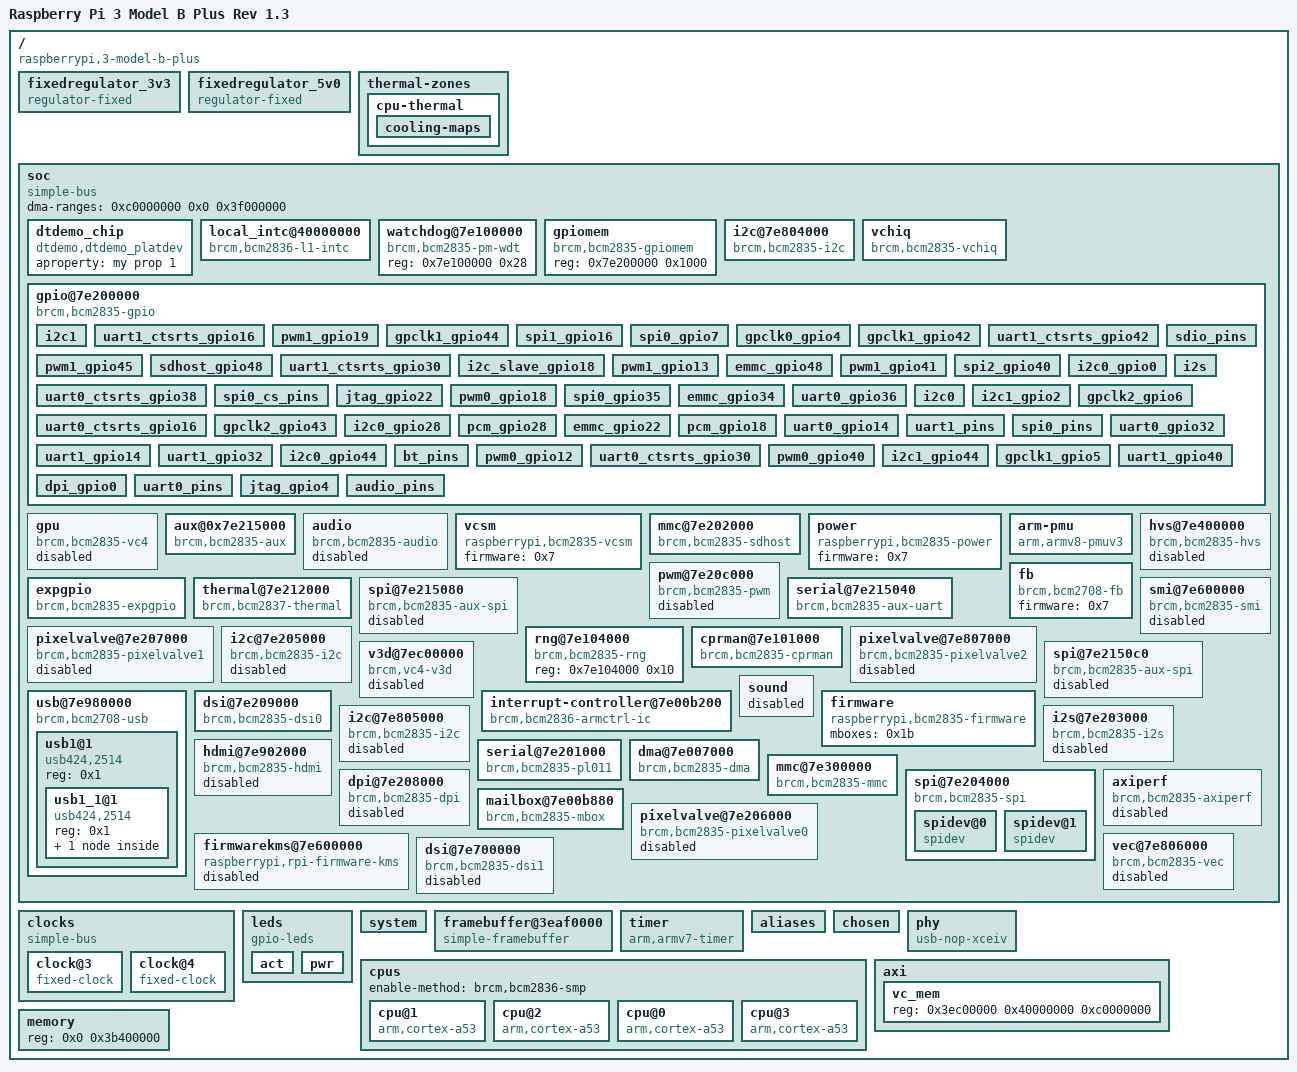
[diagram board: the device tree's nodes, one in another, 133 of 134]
/dts-v1/;

/ {
	#address-cells = <0x1>;
	memreserve = <0x3b400000 0x4c00000>;
	model = "Raspberry Pi 3 Model B Plus Rev 1.3";
	serial-number = "000000000906a583";
	#size-cells = <0x1>;
	interrupt-parent = <0x1>;
	compatible = "raspberrypi,3-model-b-plus", "brcm,bcm2837";

	fixedregulator_3v3 {
		regulator-max-microvolt = <0x325aa0>;
		regulator-always-on;
		regulator-min-microvolt = <0x325aa0>;
		regulator-name = "3v3";
		compatible = "regulator-fixed";
		phandle = <0x74>;
	};

	fixedregulator_5v0 {
		regulator-max-microvolt = <0x4c4b40>;
		regulator-always-on;
		regulator-min-microvolt = <0x4c4b40>;
		regulator-name = "5v0";
		compatible = "regulator-fixed";
		phandle = <0x73>;
	};

	thermal-zones {

		cpu-thermal {
			polling-delay = <0x3e8>;
			polling-delay-passive = <0x0>;
			thermal-sensors = <0x2>;
			phandle = <0x30>;
			coefficients = <0xfffffde6 0x64960>;

			cooling-maps {
			};
		};
	};

	soc {
		dma-ranges = <0xc0000000 0x0 0x3f000000>;
		#address-cells = <0x1>;
		#size-cells = <0x1>;
		compatible = "simple-bus";
		ranges = <0x7e000000 0x3f000000 0x1000000 0x40000000 0x40000000 0x1000>;
		phandle = <0x31>;

		/* our demo pseudo h/w chip
		From DTSpec: https://github.com/devicetree-org/devicetree-specification/releases/download/v0.3-rc2/devicetree-specification-v0.3-rc2.pdf
		 "This list of strings should be used by a client program for device driver selection. The property
value consists of a concatenated list of null terminated strings, from most specific to most general. They
allow a device to express its compatibility with a family of similar devices, potentially allowing a single
device driver to match against several devices. "
		
		*/
		dtdemo_chip {
			compatible = "dtdemo,dtdemo_platdev";
			aproperty = "my prop 1";
		};

		local_intc@40000000 {
			interrupt-parent = <0x3>;
			compatible = "brcm,bcm2836-l1-intc";
			#interrupt-cells = <0x1>;
			reg = <0x40000000 0x100>;
			phandle = <0x3>;
			interrupt-controller;
		};

		watchdog@7e100000 {
			compatible = "brcm,bcm2835-pm-wdt";
			reg = <0x7e100000 0x28>;
			phandle = <0x25>;
		};

		gpiomem {
			compatible = "brcm,bcm2835-gpiomem";
			reg = <0x7e200000 0x1000>;
		};

		i2c@7e804000 {
			pinctrl-names = "default";
			#address-cells = <0x1>;
			pinctrl-0 = <0x14>;
			interrupts = <0x2 0x15>;
			clocks = <0x8 0x14>;
			#size-cells = <0x0>;
			clock-frequency = <0x186a0>;
			compatible = "brcm,bcm2835-i2c";
			status = "okay";
			reg = <0x7e804000 0x1000>;
			phandle = <0x23>;
		};

		vchiq {
			interrupts = <0x0 0x2>;
			compatible = "brcm,bcm2835-vchiq";
			cache-line-size = <0x40>;
			firmware = <0x7>;
			reg = <0x7e00b840 0xf>;
			phandle = <0x1d>;
		};

		gpio@7e200000 {
			gpio-controller;
			interrupts = <0x2 0x11 0x2 0x12>;
			compatible = "brcm,bcm2835-gpio";
			#interrupt-cells = <0x2>;
			reg = <0x7e200000 0xb4>;
			phandle = <0x10>;
			#gpio-cells = <0x2>;
			interrupt-controller;

			i2c1 {
				brcm,function = <0x4>;
				phandle = <0x14>;
				brcm,pins = <0x2 0x3>;
			};

			uart1_ctsrts_gpio16 {
				brcm,function = <0x2>;
				phandle = <0x58>;
				brcm,pins = <0x10 0x11>;
			};

			pwm1_gpio19 {
				brcm,function = <0x2>;
				phandle = <0x4a>;
				brcm,pins = <0x13>;
			};

			gpclk1_gpio44 {
				brcm,function = <0x4>;
				phandle = <0x39>;
				brcm,pins = <0x2c>;
			};

			spi1_gpio16 {
				brcm,function = <0x3>;
				phandle = <0x4f>;
				brcm,pins = <0x10 0x11 0x12 0x13 0x14 0x15>;
			};

			spi0_gpio7 {
				brcm,function = <0x4>;
				phandle = <0x4d>;
				brcm,pins = <0x7 0x8 0x9 0xa 0xb>;
			};

			gpclk0_gpio4 {
				brcm,function = <0x4>;
				phandle = <0x36>;
				brcm,pins = <0x4>;
			};

			gpclk1_gpio42 {
				brcm,function = <0x4>;
				phandle = <0x38>;
				brcm,pins = <0x2a>;
			};

			uart1_ctsrts_gpio42 {
				brcm,function = <0x2>;
				phandle = <0x5c>;
				brcm,pins = <0x2a 0x2b>;
			};

			pwm1_gpio45 {
				brcm,function = <0x4>;
				phandle = <0x4c>;
				brcm,pins = <0x2d>;
			};

			sdhost_gpio48 {
				brcm,function = <0x4>;
				phandle = <0xc>;
				brcm,pins = <0x30 0x31 0x32 0x33 0x34 0x35>;
			};

			uart1_ctsrts_gpio30 {
				brcm,function = <0x2>;
				phandle = <0x5a>;
				brcm,pins = <0x1e 0x1f>;
			};

			i2c_slave_gpio18 {
				brcm,function = <0x7>;
				phandle = <0x41>;
				brcm,pins = <0x12 0x13 0x14 0x15>;
			};

			sdio_pins {
				brcm,pull = <0x0 0x2 0x2 0x2 0x2 0x2>;
				brcm,function = <0x7>;
				phandle = <0x1a>;
				brcm,pins = <0x22 0x23 0x24 0x25 0x26 0x27>;
			};

			pwm1_gpio13 {
				brcm,function = <0x4>;
				phandle = <0x49>;
				brcm,pins = <0xd>;
			};

			emmc_gpio48 {
				brcm,function = <0x7>;
				phandle = <0x35>;
				brcm,pins = <0x30 0x31 0x32 0x33 0x34 0x35>;
			};

			pwm1_gpio41 {
				brcm,function = <0x4>;
				phandle = <0x4b>;
				brcm,pins = <0x29>;
			};

			spi2_gpio40 {
				brcm,function = <0x3>;
				phandle = <0x50>;
				brcm,pins = <0x28 0x29 0x2a 0x2b 0x2c 0x2d>;
			};

			i2c0_gpio0 {
				brcm,function = <0x4>;
				phandle = <0x3c>;
				brcm,pins = <0x0 0x1>;
			};

			uart0_ctsrts_gpio38 {
				brcm,function = <0x6>;
				phandle = <0x56>;
				brcm,pins = <0x26 0x27>;
			};

			spi0_cs_pins {
				brcm,function = <0x1>;
				phandle = <0xf>;
				brcm,pins = <0x8 0x7>;
			};

			jtag_gpio22 {
				brcm,function = <0x3>;
				phandle = <0x43>;
				brcm,pins = <0x16 0x17 0x18 0x19 0x1a 0x1b>;
			};

			i2s {
				brcm,function = <0x4>;
				phandle = <0xd>;
				brcm,pins = <0x12 0x13 0x14 0x15>;
			};

			pwm0_gpio18 {
				brcm,function = <0x2>;
				phandle = <0x47>;
				brcm,pins = <0x12>;
			};

			spi0_gpio35 {
				brcm,function = <0x4>;
				phandle = <0x4e>;
				brcm,pins = <0x23 0x24 0x25 0x26 0x27>;
			};

			emmc_gpio34 {
				brcm,pull = <0x0 0x2 0x2 0x2 0x2 0x2>;
				brcm,function = <0x7>;
				phandle = <0x34>;
				brcm,pins = <0x22 0x23 0x24 0x25 0x26 0x27>;
			};

			uart0_gpio36 {
				brcm,function = <0x6>;
				phandle = <0x55>;
				brcm,pins = <0x24 0x25>;
			};

			i2c0 {
				brcm,function = <0x4>;
				phandle = <0x11>;
				brcm,pins = <0x0 0x1>;
			};

			i2c1_gpio2 {
				brcm,function = <0x4>;
				phandle = <0x3f>;
				brcm,pins = <0x2 0x3>;
			};

			gpclk2_gpio6 {
				brcm,function = <0x4>;
				phandle = <0x3a>;
				brcm,pins = <0x6>;
			};

			uart0_ctsrts_gpio16 {
				brcm,function = <0x7>;
				phandle = <0x52>;
				brcm,pins = <0x10 0x11>;
			};

			gpclk2_gpio43 {
				brcm,function = <0x4>;
				phandle = <0x3b>;
				brcm,pins = <0x2b>;
			};

			i2c0_gpio28 {
				brcm,function = <0x4>;
				phandle = <0x3d>;
				brcm,pins = <0x1c 0x1d>;
			};

			pcm_gpio28 {
				brcm,function = <0x6>;
				phandle = <0x45>;
				brcm,pins = <0x1c 0x1d 0x1e 0x1f>;
			};

			emmc_gpio22 {
				brcm,function = <0x7>;
				phandle = <0x33>;
				brcm,pins = <0x16 0x17 0x18 0x19 0x1a 0x1b>;
			};

			pcm_gpio18 {
				brcm,function = <0x4>;
				phandle = <0x44>;
				brcm,pins = <0x12 0x13 0x14 0x15>;
			};

			uart0_gpio14 {
				brcm,function = <0x4>;
				phandle = <0x51>;
				brcm,pins = <0xe 0xf>;
			};

			uart1_pins {
				brcm,pull;
				brcm,function;
				phandle = <0x13>;
				brcm,pins;
			};

			spi0_pins {
				brcm,function = <0x4>;
				phandle = <0xe>;
				brcm,pins = <0x9 0xa 0xb>;
			};

			uart0_gpio32 {
				brcm,function = <0x7>;
				phandle = <0x54>;
				brcm,pins = <0x20 0x21>;
			};

			uart1_gpio14 {
				brcm,function = <0x2>;
				phandle = <0x57>;
				brcm,pins = <0xe 0xf>;
			};

			uart1_gpio32 {
				brcm,function = <0x2>;
				phandle = <0x59>;
				brcm,pins = <0x20 0x21>;
			};

			i2c0_gpio44 {
				brcm,function = <0x5>;
				phandle = <0x3e>;
				brcm,pins = <0x2c 0x2d>;
			};

			bt_pins {
				brcm,pull = <0x0>;
				brcm,function = <0x4>;
				phandle = <0xa>;
				brcm,pins = <0x2b>;
			};

			pwm0_gpio12 {
				brcm,function = <0x4>;
				phandle = <0x46>;
				brcm,pins = <0xc>;
			};

			uart0_ctsrts_gpio30 {
				brcm,function = <0x7>;
				phandle = <0x53>;
				brcm,pins = <0x1e 0x1f>;
			};

			pwm0_gpio40 {
				brcm,function = <0x4>;
				phandle = <0x48>;
				brcm,pins = <0x28>;
			};

			i2c1_gpio44 {
				brcm,function = <0x6>;
				phandle = <0x40>;
				brcm,pins = <0x2c 0x2d>;
			};

			gpclk1_gpio5 {
				brcm,function = <0x4>;
				phandle = <0x37>;
				brcm,pins = <0x5>;
			};

			uart1_gpio40 {
				brcm,function = <0x2>;
				phandle = <0x5b>;
				brcm,pins = <0x28 0x29>;
			};

			dpi_gpio0 {
				brcm,function = <0x6>;
				phandle = <0x32>;
				brcm,pins = <0x0 0x1 0x2 0x3 0x4 0x5 0x6 0x7 0x8 0x9 0xa 0xb 0xc 0xd 0xe 0xf 0x10 0x11 0x12 0x13 0x14 0x15 0x16 0x17 0x18 0x19 0x1a 0x1b>;
			};

			uart0_pins {
				brcm,pull = <0x2 0x0 0x0 0x2>;
				brcm,function = <0x7>;
				phandle = <0x9>;
				brcm,pins = <0x1e 0x1f 0x20 0x21>;
			};

			jtag_gpio4 {
				brcm,function = <0x2>;
				phandle = <0x42>;
				brcm,pins = <0x4 0x5 0x6 0xc 0xd>;
			};

			audio_pins {
				brcm,function = <0x4>;
				phandle = <0x1c>;
				brcm,pins = <0x28 0x29>;
			};
		};

		gpu {
			compatible = "brcm,bcm2835-vc4";
			status = "disabled";
			phandle = <0x6a>;
		};

		aux@0x7e215000 {
			interrupts = <0x1 0x1d>;
			clocks = <0x8 0x14>;
			#clock-cells = <0x1>;
			compatible = "brcm,bcm2835-aux";
			#interrupt-cells = <0x1>;
			reg = <0x7e215000 0x8>;
			phandle = <0x12>;
			interrupt-controller;
		};

		audio {
			pinctrl-names = "default";
			brcm,pwm-channels = <0x8>;
			pinctrl-0 = <0x1c>;
			compatible = "brcm,bcm2835-audio";
			status = "disabled";
			phandle = <0x24>;
		};

		vcsm {
			compatible = "raspberrypi,bcm2835-vcsm";
			status = "okay";
			firmware = <0x7>;
			phandle = <0x70>;
		};

		mmc@7e202000 {
			pinctrl-names = "default";
			pinctrl-0 = <0xc>;
			bus-width = <0x4>;
			interrupts = <0x2 0x18>;
			clocks = <0x8 0x14>;
			brcm,pio-limit = <0x1>;
			dma-names = "rx-tx";
			compatible = "brcm,bcm2835-sdhost";
			status = "okay";
			reg = <0x7e202000 0x100>;
			phandle = <0x27>;
			dmas = <0xb 0xd>;
			brcm,overclock-50 = <0x0>;
		};

		power {
			#power-domain-cells = <0x1>;
			compatible = "raspberrypi,bcm2835-power";
			firmware = <0x7>;
			phandle = <0x16>;
		};

		arm-pmu {
			interrupts = <0x9>;
			interrupt-parent = <0x3>;
			compatible = "arm,armv8-pmuv3", "arm,cortex-a7-pmu";
		};

		hvs@7e400000 {
			interrupts = <0x2 0x1>;
			compatible = "brcm,bcm2835-hvs";
			status = "disabled";
			reg = <0x7e400000 0x6000>;
			phandle = <0x64>;
		};

		expgpio {
			gpio-controller;
			compatible = "brcm,bcm2835-expgpio";
			status = "okay";
			firmware = <0x7>;
			phandle = <0x17>;
			#gpio-cells = <0x2>;
		};

		pwm@7e20c000 {
			assigned-clocks = <0x8 0x1e>;
			assigned-clock-rates = <0x989680>;
			clocks = <0x8 0x1e>;
			#pwm-cells = <0x2>;
			compatible = "brcm,bcm2835-pwm";
			status = "disabled";
			reg = <0x7e20c000 0x28>;
			phandle = <0x63>;
		};

		fb {
			compatible = "brcm,bcm2708-fb";
			status = "okay";
			firmware = <0x7>;
			phandle = <0x6f>;
		};

		thermal@7e212000 {
			clocks = <0x8 0x1b>;
			#thermal-sensor-cells = <0x0>;
			compatible = "brcm,bcm2837-thermal";
			status = "okay";
			reg = <0x7e212000 0x8>;
			phandle = <0x2>;
		};

		spi@7e215080 {
			#address-cells = <0x1>;
			interrupts = <0x1>;
			clocks = <0x12 0x1>;
			#size-cells = <0x0>;
			interrupt-parent = <0x12>;
			compatible = "brcm,bcm2835-aux-spi";
			status = "disabled";
			reg = <0x7e215080 0x40>;
			phandle = <0x61>;
		};

		serial@7e215040 {
			pinctrl-names = "default";
			pinctrl-0 = <0x13>;
			interrupts = <0x0>;
			clocks = <0x12 0x0>;
			interrupt-parent = <0x12>;
			compatible = "brcm,bcm2835-aux-uart";
			status = "okay";
			reg = <0x7e215040 0x40>;
			phandle = <0x1f>;
		};

		pixelvalve@7e207000 {
			interrupts = <0x2 0xe>;
			compatible = "brcm,bcm2835-pixelvalve1";
			status = "disabled";
			reg = <0x7e207000 0x100>;
			phandle = <0x60>;
		};

		rng@7e104000 {
			compatible = "brcm,bcm2835-rng";
			reg = <0x7e104000 0x10>;
			phandle = <0x26>;
		};

		smi@7e600000 {
			assigned-clocks = <0x8 0x2a>;
			assigned-clock-rates = <0x7735940>;
			interrupts = <0x2 0x10>;
			clocks = <0x8 0x2a>;
			dma-names = "rx-tx";
			compatible = "brcm,bcm2835-smi";
			status = "disabled";
			reg = <0x7e600000 0x100>;
			phandle = <0x6e>;
			dmas = <0xb 0x4>;
		};

		cprman@7e101000 {
			clocks = <0x4 0x5 0x0 0x5 0x1 0x5 0x2 0x6 0x0 0x6 0x1 0x6 0x2>;
			#clock-cells = <0x1>;
			compatible = "brcm,bcm2835-cprman";
			firmware = <0x7>;
			reg = <0x7e101000 0x2000>;
			phandle = <0x8>;
		};

		pixelvalve@7e807000 {
			interrupts = <0x2 0xa>;
			compatible = "brcm,bcm2835-pixelvalve2";
			status = "disabled";
			reg = <0x7e807000 0x100>;
			phandle = <0x66>;
		};

		i2c@7e205000 {
			pinctrl-names = "default";
			#address-cells = <0x1>;
			pinctrl-0 = <0x11>;
			interrupts = <0x2 0x15>;
			clocks = <0x8 0x14>;
			#size-cells = <0x0>;
			clock-frequency = <0x186a0>;
			compatible = "brcm,bcm2835-i2c";
			status = "disabled";
			reg = <0x7e205000 0x1000>;
			phandle = <0x22>;
		};

		v3d@7ec00000 {
			power-domains = <0x16 0xa>;
			interrupts = <0x1 0xa>;
			compatible = "brcm,vc4-v3d";
			status = "disabled";
			reg = <0x7ec00000 0x1000>;
			phandle = <0x69>;
		};

		spi@7e2150c0 {
			#address-cells = <0x1>;
			interrupts = <0x2>;
			clocks = <0x12 0x2>;
			#size-cells = <0x0>;
			interrupt-parent = <0x12>;
			compatible = "brcm,bcm2835-aux-spi";
			status = "disabled";
			reg = <0x7e2150c0 0x40>;
			phandle = <0x62>;
		};

		usb@7e980000 {
			power-domains = <0x16 0x6>;
			#address-cells = <0x1>;
			phy-names = "usb2-phy";
			clock-names = "otg";
			interrupts = <0x2 0x0 0x1 0x9>;
			clocks = <0x18>;
			#size-cells = <0x0>;
			compatible = "brcm,bcm2708-usb";
			phys = <0x19>;
			reg = <0x7e980000 0x10000 0x7e006000 0x1000>;
			phandle = <0x68>;

			usb1@1 {
				#address-cells = <0x1>;
				#size-cells = <0x0>;
				compatible = "usb424,2514";
				reg = <0x1>;

				usb1_1@1 {
					#address-cells = <0x1>;
					#size-cells = <0x0>;
					compatible = "usb424,2514";
					reg = <0x1>;

					usbether@1 {
						local-mac-address = [b8 27 eb 06 a5 83];
						microchip,led-modes = <0x1 0x6>;
						microchip,tx-lpi-timer = <0x258>;
						compatible = "usb424,7800";
						reg = <0x1>;
						phandle = <0x2d>;
						microchip,eee-enabled;
					};
				};
			};
		};

		interrupt-controller@7e00b200 {
			interrupts = <0x8>;
			interrupt-parent = <0x3>;
			compatible = "brcm,bcm2836-armctrl-ic";
			#interrupt-cells = <0x2>;
			reg = <0x7e00b200 0x200>;
			phandle = <0x1>;
			interrupt-controller;
		};

		sound {
			status = "disabled";
			phandle = <0x71>;
		};

		firmware {
			compatible = "raspberrypi,bcm2835-firmware";
			phandle = <0x7>;
			mboxes = <0x1b>;
		};

		dsi@7e209000 {
			#address-cells = <0x1>;
			clock-output-names = "dsi0_byte", "dsi0_ddr2", "dsi0_ddr";
			clock-names = "phy", "escape", "pixel";
			interrupts = <0x2 0x4>;
			clocks = <0x8 0x20 0x8 0x2f 0x8 0x31>;
			#size-cells = <0x0>;
			#clock-cells = <0x1>;
			compatible = "brcm,bcm2835-dsi0";
			reg = <0x7e209000 0x78>;
			phandle = <0x5>;
		};

		i2c@7e805000 {
			#address-cells = <0x1>;
			interrupts = <0x2 0x15>;
			clocks = <0x8 0x14>;
			#size-cells = <0x0>;
			clock-frequency = <0x186a0>;
			compatible = "brcm,bcm2835-i2c";
			status = "disabled";
			reg = <0x7e805000 0x1000>;
			phandle = <0x15>;
		};

		i2s@7e203000 {
			pinctrl-names = "default";
			pinctrl-0 = <0xd>;
			clocks = <0x8 0x1f>;
			dma-names = "tx", "rx";
			#sound-dai-cells = <0x0>;
			compatible = "brcm,bcm2835-i2s";
			status = "disabled";
			reg = <0x7e203000 0x24>;
			phandle = <0x20>;
			dmas = <0xb 0x2 0xb 0x3>;
		};

		hdmi@7e902000 {
			power-domains = <0x16 0x5>;
			hpd-gpios = <0x17 0x4 0x1>;
			clock-names = "pixel", "hdmi";
			interrupts = <0x2 0x8 0x2 0x9>;
			clocks = <0x8 0x10 0x8 0x19>;
			ddc = <0x15>;
			dma-names = "audio-rx";
			compatible = "brcm,bcm2835-hdmi";
			status = "disabled";
			reg = <0x7e902000 0x600 0x7e808000 0x100>;
			phandle = <0x67>;
			dmas = <0xb 0x11>;
		};

		serial@7e201000 {
			arm,primecell-periphid = <0x241011>;
			pinctrl-names = "default";
			pinctrl-0 = <0x9 0xa>;
			clock-names = "uartclk", "apb_pclk";
			cts-event-workaround;
			interrupts = <0x2 0x19>;
			clocks = <0x8 0x13 0x8 0x14>;
			compatible = "brcm,bcm2835-pl011", "arm,pl011", "arm,primecell";
			status = "okay";
			reg = <0x7e201000 0x1000>;
			phandle = <0x1e>;
		};

		dma@7e007000 {
			interrupts = <0x1 0x10 0x1 0x11 0x1 0x12 0x1 0x13 0x1 0x14 0x1 0x15 0x1 0x16 0x1 0x17 0x1 0x18 0x1 0x19 0x1 0x1a 0x1 0x1b 0x1 0x1b 0x1 0x1b 0x1 0x1b 0x1 0x1c>;
			brcm,dma-channel-mask = <0x7f34>;
			compatible = "brcm,bcm2835-dma";
			interrupt-names = "dma0", "dma1", "dma2", "dma3", "dma4", "dma5", "dma6", "dma7", "dma8", "dma9", "dma10", "dma11", "dma12", "dma13", "dma14", "dma-shared-all";
			reg = <0x7e007000 0xf00>;
			phandle = <0xb>;
			#dma-cells = <0x1>;
		};

		mmc@7e300000 {
			pinctrl-names = "default";
			pinctrl-0 = <0x1a>;
			bus-width = <0x4>;
			non-removable;
			interrupts = <0x2 0x1e>;
			clocks = <0x8 0x1c>;
			dma-names = "rx-tx";
			compatible = "brcm,bcm2835-mmc", "brcm,bcm2835-sdhci";
			status = "okay";
			reg = <0x7e300000 0x100>;
			phandle = <0x6c>;
			dmas = <0xb 0xb>;
			brcm,overclock-50 = <0x0>;
		};

		spi@7e204000 {
			pinctrl-names = "default";
			#address-cells = <0x1>;
			pinctrl-0 = <0xe 0xf>;
			interrupts = <0x2 0x16>;
			clocks = <0x8 0x14>;
			#size-cells = <0x0>;
			dma-names = "tx", "rx";
			compatible = "brcm,bcm2835-spi";
			status = "okay";
			reg = <0x7e204000 0x1000>;
			phandle = <0x21>;
			dmas = <0xb 0x6 0xb 0x7>;
			cs-gpios = <0x10 0x8 0x1 0x10 0x7 0x1>;

			spidev@0 {
				#address-cells = <0x1>;
				#size-cells = <0x0>;
				spi-max-frequency = <0x7735940>;
				compatible = "spidev";
				reg = <0x0>;
				phandle = <0x5d>;
			};

			spidev@1 {
				#address-cells = <0x1>;
				#size-cells = <0x0>;
				spi-max-frequency = <0x7735940>;
				compatible = "spidev";
				reg = <0x1>;
				phandle = <0x5e>;
			};
		};

		dpi@7e208000 {
			#address-cells = <0x1>;
			clock-names = "core", "pixel";
			clocks = <0x8 0x14 0x8 0x2c>;
			#size-cells = <0x0>;
			compatible = "brcm,bcm2835-dpi";
			status = "disabled";
			reg = <0x7e208000 0x8c>;
			phandle = <0x6b>;
		};

		axiperf {
			compatible = "brcm,bcm2835-axiperf";
			status = "disabled";
			firmware = <0x7>;
			reg = <0x7e009800 0x100 0x7ee08000 0x100>;
			phandle = <0x28>;
		};

		mailbox@7e00b880 {
			interrupts = <0x0 0x1>;
			#mbox-cells = <0x0>;
			compatible = "brcm,bcm2835-mbox";
			reg = <0x7e00b880 0x40>;
			phandle = <0x1b>;
		};

		pixelvalve@7e206000 {
			interrupts = <0x2 0xd>;
			compatible = "brcm,bcm2835-pixelvalve0";
			status = "disabled";
			reg = <0x7e206000 0x100>;
			phandle = <0x5f>;
		};

		firmwarekms@7e600000 {
			brcm,firmware = <0x7>;
			interrupts = <0x2 0x10>;
			compatible = "raspberrypi,rpi-firmware-kms";
			status = "disabled";
			reg = <0x7e600000 0x100>;
			phandle = <0x6d>;
		};

		vec@7e806000 {
			interrupts = <0x2 0x1b>;
			clocks = <0x8 0x18>;
			compatible = "brcm,bcm2835-vec";
			status = "disabled";
			reg = <0x7e806000 0x1000>;
			phandle = <0x65>;
		};

		dsi@7e700000 {
			#address-cells = <0x1>;
			clock-output-names = "dsi1_byte", "dsi1_ddr2", "dsi1_ddr";
			clock-names = "phy", "escape", "pixel";
			interrupts = <0x2 0xc>;
			clocks = <0x8 0x23 0x8 0x30 0x8 0x32>;
			#size-cells = <0x0>;
			#clock-cells = <0x1>;
			compatible = "brcm,bcm2835-dsi1";
			status = "disabled";
			reg = <0x7e700000 0x8c>;
			phandle = <0x6>;
		};
	};

	clocks {
		#address-cells = <0x1>;
		#size-cells = <0x0>;
		compatible = "simple-bus";

		clock@3 {
			clock-output-names = "osc";
			#clock-cells = <0x0>;
			clock-frequency = <0x124f800>;
			compatible = "fixed-clock";
			reg = <0x3>;
			phandle = <0x4>;
		};

		clock@4 {
			clock-output-names = "otg";
			#clock-cells = <0x0>;
			clock-frequency = <0x1c9c3800>;
			compatible = "fixed-clock";
			reg = <0x4>;
			phandle = <0x18>;
		};
	};

	leds {
		compatible = "gpio-leds";
		phandle = <0x75>;

		act {
			linux,default-trigger = "mmc0";
			label = "led0";
			phandle = <0x2e>;
			gpios = <0x10 0x1d 0x0>;
		};

		pwr {
			linux,default-trigger = "default-on";
			label = "led1";
			phandle = <0x2f>;
			gpios = <0x17 0x2 0x1>;
		};
	};

	system {
		linux,serial = <0x0 0x906a583>;
		linux,revision = <0xa020d3>;
	};

	framebuffer@3eaf0000 {
		format = "a8r8g8b8";
		height = <0x1a0>;
		width = <0x290>;
		stride = <0xa40>;
		compatible = "simple-framebuffer";
		status = "okay";
		reg = <0x3eaf0000 0x10a800>;
	};

	timer {
		always-on;
		interrupts = <0x0 0x1 0x3 0x2>;
		interrupt-parent = <0x3>;
		compatible = "arm,armv7-timer";
	};

	aliases {
		ethernet0 = "/soc/usb@7e980000/usb1@1/usb1_1@1/usbether@1";
		thermal = "/soc/thermal@7e212000";
		intc = "/soc/interrupt-controller@7e00b200";
		spi2 = "/soc/spi@7e2150c0";
		i2c1 = "/soc/i2c@7e804000";
		vchiq = "/soc/vchiq";
		spi0 = "/soc/spi@7e204000";
		random = "/soc/rng@7e104000";
		audio = "/soc/audio";
		aux = "/soc/aux@0x7e215000";
		gpio = "/soc/gpio@7e200000";
		mmc1 = "/soc/mmc@7e300000";
		dma = "/soc/dma@7e007000";
		mailbox = "/soc/mailbox@7e00b880";
		soc = "/soc";
		sdhost = "/soc/mmc@7e202000";
		serial1 = "/soc/serial@7e201000";
		i2c_vc = "/soc/i2c@7e205000";
		leds = "/leds";
		uart0 = "/soc/serial@7e201000";
		mmc = "/soc/mmc@7e300000";
		i2c_arm = "/soc/i2c@7e804000";
		fb = "/soc/fb";
		i2c2 = "/soc/i2c@7e805000";
		spi1 = "/soc/spi@7e215080";
		i2s = "/soc/i2s@7e203000";
		usb = "/soc/usb@7e980000";
		i2c0 = "/soc/i2c@7e205000";
		sound = "/soc/sound";
		mmc0 = "/soc/mmc@7e202000";
		axiperf = "/soc/axiperf";
		uart1 = "/soc/serial@7e215040";
		serial0 = "/soc/serial@7e215040";
		watchdog = "/soc/watchdog@7e100000";
		i2c = "/soc/i2c@7e804000";
	};

	chosen {
		linux,initrd-end = <0x434aa99>;
		bootargs = "8250.nr_uarts=1 bcm2708_fb.fbwidth=656 bcm2708_fb.fbheight=416 bcm2708_fb.fbswap=1 vc_mem.mem_base=0x3ec00000 vc_mem.mem_size=0x40000000  net.ifnames=0 dwc_otg.lpm_enable=0 console=ttyS0,115200 console=tty1 root=/dev/mmcblk0p2 rootfstype=ext4 elevator=deadline rootwait";
		kaslr-seed = <0x0 0x0>;
		linux,initrd-start = <0x3100000>;
	};

	phy {
		#phy-cells = <0x0>;
		compatible = "usb-nop-xceiv";
		phandle = <0x19>;
	};

	cpus {
		#address-cells = <0x1>;
		#size-cells = <0x0>;
		enable-method = "brcm,bcm2836-smp";
		phandle = <0x72>;

		cpu@1 {
			clock-frequency = "SrN";
			device_type = "cpu";
			compatible = "arm,cortex-a53";
			reg = <0x1>;
			enable-method = "spin-table";
			phandle = <0x2a>;
			cpu-release-addr = <0x0 0xe0>;
		};

		cpu@2 {
			clock-frequency = "SrN";
			device_type = "cpu";
			compatible = "arm,cortex-a53";
			reg = <0x2>;
			enable-method = "spin-table";
			phandle = <0x2b>;
			cpu-release-addr = <0x0 0xe8>;
		};

		cpu@0 {
			clock-frequency = "SrN";
			device_type = "cpu";
			compatible = "arm,cortex-a53";
			reg = <0x0>;
			enable-method = "spin-table";
			phandle = <0x29>;
			cpu-release-addr = <0x0 0xd8>;
		};

		cpu@3 {
			clock-frequency = "SrN";
			device_type = "cpu";
			compatible = "arm,cortex-a53";
			reg = <0x3>;
			enable-method = "spin-table";
			phandle = <0x2c>;
			cpu-release-addr = <0x0 0xf0>;
		};
	};

	__symbols__ {
		pwm = "/soc/pwm@7e20c000";
		thermal = "/soc/thermal@7e212000";
		intc = "/soc/interrupt-controller@7e00b200";
		act_led = "/leds/act";
		clk_usb = "/clocks/clock@4";
		spi2 = "/soc/spi@7e2150c0";
		pixelvalve0 = "/soc/pixelvalve@7e206000";
		dsi1 = "/soc/dsi@7e700000";
		vdd_3v3_reg = "/fixedregulator_3v3";
		i2c1 = "/soc/i2c@7e804000";
		vchiq = "/soc/vchiq";
		uart1_ctsrts_gpio16 = "/soc/gpio@7e200000/uart1_ctsrts_gpio16";
		pwm1_gpio19 = "/soc/gpio@7e200000/pwm1_gpio19";
		gpclk1_gpio44 = "/soc/gpio@7e200000/gpclk1_gpio44";
		smi = "/soc/smi@7e600000";
		spidev1 = "/soc/spi@7e204000/spidev@1";
		spi0 = "/soc/spi@7e204000";
		random = "/soc/rng@7e104000";
		spi1_gpio16 = "/soc/gpio@7e200000/spi1_gpio16";
		audio = "/soc/audio";
		aux = "/soc/aux@0x7e215000";
		gpio = "/soc/gpio@7e200000";
		spi0_gpio7 = "/soc/gpio@7e200000/spi0_gpio7";
		gpclk0_gpio4 = "/soc/gpio@7e200000/gpclk0_gpio4";
		gpclk1_gpio42 = "/soc/gpio@7e200000/gpclk1_gpio42";
		uart1_ctsrts_gpio42 = "/soc/gpio@7e200000/uart1_ctsrts_gpio42";
		pwm1_gpio45 = "/soc/gpio@7e200000/pwm1_gpio45";
		vcsm = "/soc/vcsm";
		dpi = "/soc/dpi@7e208000";
		v3d = "/soc/v3d@7ec00000";
		sdhost_gpio48 = "/soc/gpio@7e200000/sdhost_gpio48";
		dma = "/soc/dma@7e007000";
		cpu_thermal = "/thermal-zones/cpu-thermal";
		power = "/soc/power";
		i2s_pins = "/soc/gpio@7e200000/i2s";
		vc4 = "/soc/gpu";
		cpu3 = "/cpus/cpu@3";
		mailbox = "/soc/mailbox@7e00b880";
		uart1_ctsrts_gpio30 = "/soc/gpio@7e200000/uart1_ctsrts_gpio30";
		soc = "/soc";
		i2c_slave_gpio18 = "/soc/gpio@7e200000/i2c_slave_gpio18";
		sdio_pins = "/soc/gpio@7e200000/sdio_pins";
		clocks = "/soc/cprman@7e101000";
		sdhost = "/soc/mmc@7e202000";
		i2c_vc = "/soc/i2c@7e205000";
		leds = "/leds";
		pwm1_gpio13 = "/soc/gpio@7e200000/pwm1_gpio13";
		emmc_gpio48 = "/soc/gpio@7e200000/emmc_gpio48";
		pwm1_gpio41 = "/soc/gpio@7e200000/pwm1_gpio41";
		cpu1 = "/cpus/cpu@1";
		uart0 = "/soc/serial@7e201000";
		firmwarekms = "/soc/firmwarekms@7e600000";
		local_intc = "/soc/local_intc@40000000";
		spi2_gpio40 = "/soc/gpio@7e200000/spi2_gpio40";
		mmc = "/soc/mmc@7e300000";
		expgpio = "/soc/expgpio";
		spi = "/soc/spi@7e204000";
		i2c_arm = "/soc/i2c@7e804000";
		i2c0_gpio0 = "/soc/gpio@7e200000/i2c0_gpio0";
		pixelvalve1 = "/soc/pixelvalve@7e207000";
		fb = "/soc/fb";
		uart0_ctsrts_gpio38 = "/soc/gpio@7e200000/uart0_ctsrts_gpio38";
		clk_osc = "/clocks/clock@3";
		i2c2 = "/soc/i2c@7e805000";
		spi0_cs_pins = "/soc/gpio@7e200000/spi0_cs_pins";
		jtag_gpio22 = "/soc/gpio@7e200000/jtag_gpio22";
		i2c1_pins = "/soc/gpio@7e200000/i2c1";
		spi1 = "/soc/spi@7e215080";
		usbphy = "/phy";
		i2s = "/soc/i2s@7e203000";
		dsi0 = "/soc/dsi@7e209000";
		pwm0_gpio18 = "/soc/gpio@7e200000/pwm0_gpio18";
		spi0_gpio35 = "/soc/gpio@7e200000/spi0_gpio35";
		usb = "/soc/usb@7e980000";
		emmc_gpio34 = "/soc/gpio@7e200000/emmc_gpio34";
		uart0_gpio36 = "/soc/gpio@7e200000/uart0_gpio36";
		i2c0 = "/soc/i2c@7e205000";
		i2c1_gpio2 = "/soc/gpio@7e200000/i2c1_gpio2";
		gpclk2_gpio6 = "/soc/gpio@7e200000/gpclk2_gpio6";
		uart0_ctsrts_gpio16 = "/soc/gpio@7e200000/uart0_ctsrts_gpio16";
		spidev0 = "/soc/spi@7e204000/spidev@0";
		sound = "/soc/sound";
		pwr_led = "/leds/pwr";
		firmware = "/soc/firmware";
		vec = "/soc/vec@7e806000";
		gpclk2_gpio43 = "/soc/gpio@7e200000/gpclk2_gpio43";
		i2c0_gpio28 = "/soc/gpio@7e200000/i2c0_gpio28";
		pcm_gpio28 = "/soc/gpio@7e200000/pcm_gpio28";
		emmc_gpio22 = "/soc/gpio@7e200000/emmc_gpio22";
		i2c0_pins = "/soc/gpio@7e200000/i2c0";
		pcm_gpio18 = "/soc/gpio@7e200000/pcm_gpio18";
		hvs = "/soc/hvs@7e400000";
		uart0_gpio14 = "/soc/gpio@7e200000/uart0_gpio14";
		uart1_pins = "/soc/gpio@7e200000/uart1_pins";
		spi0_pins = "/soc/gpio@7e200000/spi0_pins";
		ethernet = "/soc/usb@7e980000/usb1@1/usb1_1@1/usbether@1";
		uart0_gpio32 = "/soc/gpio@7e200000/uart0_gpio32";
		uart1_gpio14 = "/soc/gpio@7e200000/uart1_gpio14";
		axiperf = "/soc/axiperf";
		vdd_5v0_reg = "/fixedregulator_5v0";
		cpus = "/cpus";
		cpu2 = "/cpus/cpu@2";
		uart1_gpio32 = "/soc/gpio@7e200000/uart1_gpio32";
		uart1 = "/soc/serial@7e215040";
		i2c0_gpio44 = "/soc/gpio@7e200000/i2c0_gpio44";
		hdmi = "/soc/hdmi@7e902000";
		bt_pins = "/soc/gpio@7e200000/bt_pins";
		pwm0_gpio12 = "/soc/gpio@7e200000/pwm0_gpio12";
		uart0_ctsrts_gpio30 = "/soc/gpio@7e200000/uart0_ctsrts_gpio30";
		pwm0_gpio40 = "/soc/gpio@7e200000/pwm0_gpio40";
		i2c1_gpio44 = "/soc/gpio@7e200000/i2c1_gpio44";
		gpclk1_gpio5 = "/soc/gpio@7e200000/gpclk1_gpio5";
		uart1_gpio40 = "/soc/gpio@7e200000/uart1_gpio40";
		dpi_gpio0 = "/soc/gpio@7e200000/dpi_gpio0";
		sdhost_pins = "/soc/gpio@7e200000/sdhost_gpio48";
		watchdog = "/soc/watchdog@7e100000";
		pixelvalve2 = "/soc/pixelvalve@7e807000";
		uart0_pins = "/soc/gpio@7e200000/uart0_pins";
		cpu0 = "/cpus/cpu@0";
		jtag_gpio4 = "/soc/gpio@7e200000/jtag_gpio4";
		i2c = "/soc/i2c@7e804000";
		audio_pins = "/soc/gpio@7e200000/audio_pins";
	};

	axi {

		vc_mem {
			reg = <0x3ec00000 0x40000000 0xc0000000>;
		};
	};

	__overrides__ {
		i2c1 = "", "", "", "#status";
		random = "", "", "", "&status";
		sd_overclock = "", "", "", "'brcm,overclock-50:0";
		audio = "", "", "", "$status";
		cache_line_size = [00 00 00 1d 63 61 63 68 65 2d 6c 69 6e 65 2d 73 69 7a 65 3a 30 00];
		arm_freq = "", "", "", ")clock-frequency:0", "", "", "", "*clock-frequency:0", "", "", "", "+clock-frequency:0", "", "", "", ",clock-frequency:0";
		sd_force_pio = "", "", "", "'brcm,force-pio?";
		i2c0_baudrate = "", "", "", "\"clock-frequency:0";
		i2c_vc = "", "", "", "\"status";
		uart0 = [00 00 00 1e 73 74 61 74 75 73 00];
		eth_led1 = "", "", "", "-microchip,led-modes:4";
		pwr_led_gpio = "", "", "", "/gpios:4";
		act_led_gpio = "", "", "", ".gpios:4";
		spi = "", "", "", "!status";
		i2c_arm = "", "", "", "#status";
		i2c1_baudrate = "", "", "", "#clock-frequency:0";
		act_led_activelow = "", "", "", ".gpios:8";
		i2s = "", "", "", " status";
		i2c_vc_baudrate = "", "", "", "\"clock-frequency:0";
		i2c0 = "", "", "", "\"status";
		tx_lpi_timer = "", "", "", "-microchip,tx-lpi-timer:0";
		sd_debug = "", "", "", "'brcm,debug";
		i2c2_baudrate = [00 00 00 15 63 6c 6f 63 6b 2d 66 72 65 71 75 65 6e 63 79 3a 30 00];
		i2c_baudrate = "", "", "", "#clock-frequency:0";
		sd_pio_limit = "", "", "", "'brcm,pio-limit:0";
		pwr_led_trigger = "", "", "", "/linux,default-trigger";
		i2c_arm_baudrate = "", "", "", "#clock-frequency:0";
		pwr_led_activelow = "", "", "", "/gpios:8";
		axiperf = "", "", "", "(status";
		uart1 = [00 00 00 1f 73 74 61 74 75 73 00];
		i2c2_iknowwhatimdoing = [00 00 00 15 73 74 61 74 75 73 00];
		watchdog = "", "", "", "%status";
		i2c = "", "", "", "#status";
		act_led_trigger = "", "", "", ".linux,default-trigger";
		eth_led0 = "", "", "", "-microchip,led-modes:0";
		eee = "", "", "", "-microchip,eee-enabled?";
	};

	memory {
		device_type = "memory";
		reg = <0x0 0x3b400000>;
	};
};
